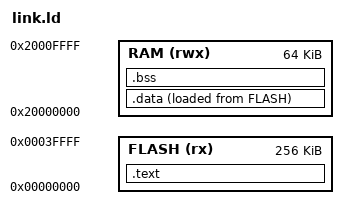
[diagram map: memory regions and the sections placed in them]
/* LM3S6965: 256 KiB flash at 0, 64 KiB SRAM at 0x20000000. */
MEMORY
{
  FLASH (rx)  : ORIGIN = 0x00000000, LENGTH = 256K
  RAM   (rwx) : ORIGIN = 0x20000000, LENGTH = 64K
}

STACK_SIZE = 4K;
ENTRY(Reset_Handler)

SECTIONS
{
  .text :
  {
    KEEP(*(.isr_vector))
    *(.text*)
    *(.rodata*)
  } > FLASH

  .data :
  {
    _sdata = .;
    *(.data*)
    . = ALIGN(4);
    _edata = .;
  } > RAM AT > FLASH
  _sidata = LOADADDR(.data);

  .bss (NOLOAD) :
  {
    _sbss = .;
    *(.bss*)
    *(COMMON)
    . = ALIGN(4);
    _ebss = .;
  } > RAM

  _estack = ORIGIN(RAM) + LENGTH(RAM);
  _sstack = _estack - STACK_SIZE;
  ASSERT(_ebss <= _sstack, "bss runs into the stack")

  /DISCARD/ : { *(.ARM.exidx*) *(.comment) }
}
